# FM33FK5XX register map
File version: 1.0
CPU: Cortex-M33 r1p0, little endian, MPU, FPU, 3 interrupt priority bits
Registers are 32-bit, read-write, reset 0x0 unless marked. A register's access mark holds for its fields unless they carry their own. Offsets are from the block's base; [hi:lo] are bit positions; {n}, {i} and the like mark numbered series.

## CMU — CMU module information
Base 0x40002400
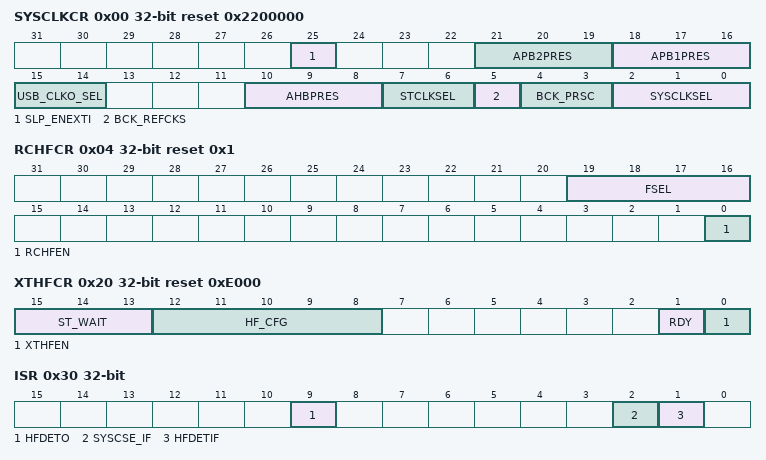
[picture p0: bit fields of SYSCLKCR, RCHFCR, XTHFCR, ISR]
0x00 SYSCLKCR reset 0x2200000 — SystemClockControlRegister
  [25] SLP_ENEXTI — SLP_ENEXTI field description
  [21:19] APB2PRES — APB2PRES field description
  [18:16] APB1PRES — APB1PRES field description
  [15:14] USB_CLKO_SEL — USB_CLKO_SEL field description
  [10:8] AHBPRES — AHBPRES field description
  [7:6] STCLKSEL — STCLKSEL field description
  [5] BCK_REFCKS — BCK_REFCKS field description
  [4:3] BCK_PRSC — BCK_PRSC field description
  [2:0] SYSCLKSEL — SYSCLKSEL field description
0x04 RCHFCR reset 0x1 — RCHFControlRegister
  [19:16] FSEL — FSEL field description
  [0] RCHFEN — RCHFEN field description
0x08 RCHFTR reset 0x80 — RCHFTrimRegister
  [7:0] RCHFTRIM — RCHFTRIM field description
0x10 RCLPCR — RCLPControlRegister
  [0] RCLP_ENB — RCLP_ENB field description
0x14 RCLPTR reset 0x80 — RCLPTrimRegister
  [7:0] RCLP_TRIM — RCLP_TRIM field description
0x20 XTHFCR access per field reset 0xE000 — XTHFControlRegister
  [15:13] ST_WAIT rw — ST_WAIT field description
  [12:8] HF_CFG rw — HF_CFG field description
  [1] RDY ro — RDY field description
  [0] XTHFEN rw — XTHFEN field description
0x2C IER — InterruptEnableRegister
  [1] HFDET_IE — HFDET_IE field description
0x30 ISR access per field — InterruptStatusRegister
  [9] HFDETO ro — HFDETO field description
  [2] SYSCSE_IF rw — SYSCSE_IF field description
  [1] HFDETIF rw — HFDETIF field description
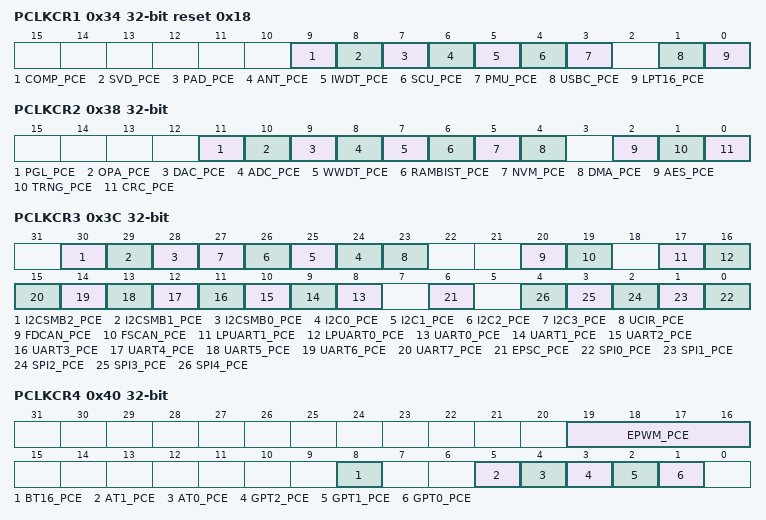
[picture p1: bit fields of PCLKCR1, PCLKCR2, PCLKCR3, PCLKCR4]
0x34 PCLKCR1 reset 0x18 — PeripheralbusClockControlRegister1
  [9] COMP_PCE — COMP_PCE field description
  [8] SVD_PCE — SVD_PCE field description
  [7] PAD_PCE — PAD_PCE field description
  [6] ANT_PCE — ANT_PCE field description
  [5] IWDT_PCE — IWDT_PCE field description
  [4] SCU_PCE — SCU_PCE field description
  [3] PMU_PCE — PMU_PCE field description
  [1] USBC_PCE — USBC_PCE field description
  [0] LPT16_PCE — LPT16_PCE field description
0x38 PCLKCR2 — PeripheralbusClockControlRegister2
  [11] PGL_PCE — PGL_PCE field description
  [10] OPA_PCE — OPA_PCE field description
  [9] DAC_PCE — DAC_PCE field description
  [8] ADC_PCE — ADC_PCE field description
  [7] WWDT_PCE — WWDT_PCE field description
  [6] RAMBIST_PCE — RAMBIST_PCE field description
  [5] NVM_PCE — NVM_PCE field description
  [4] DMA_PCE — DMA_PCE field description
  [2] AES_PCE — AES_PCE field description
  [1] TRNG_PCE — TRNG_PCE field description
  [0] CRC_PCE — CRC_PCE field description
0x3C PCLKCR3 — PeripheralbusClockControlRegister3
  [30] I2CSMB2_PCE — I2CSMB2_PCE field description
  [29] I2CSMB1_PCE — I2CSMB1_PCE field description
  [28] I2CSMB0_PCE — I2CSMB0_PCE field description
  [n+24] I2C{n}_PCE (n=0..3) — I2C{n}_PCE field description
  [23] UCIR_PCE — UCIR_PCE field description
  [20] FDCAN_PCE — FDCAN_PCE field description
  [19] FSCAN_PCE — FSCAN_PCE field description
  [17] LPUART1_PCE — LPUART1_PCE field description
  [16] LPUART0_PCE — LPUART0_PCE field description
  [n+8] UART{n}_PCE (n=0..7) — UART{n}_PCE field description
  [6] EPSC_PCE — EPSC_PCE field description
  [n] SPI{n}_PCE (n=0..4) — SPI{n}_PCE field description
0x40 PCLKCR4 — PeripheralbusClockControlRegister4
  [19:16] EPWM_PCE — EPWM_PCE field description
  [8] BT16_PCE — BT16_PCE field description
  [5] AT1_PCE — AT1_PCE field description
  [4] AT0_PCE — AT0_PCE field description
  [3] GPT2_PCE — GPT2_PCE field description
  [2] GPT1_PCE — GPT1_PCE field description
  [1] GPT0_PCE — GPT0_PCE field description
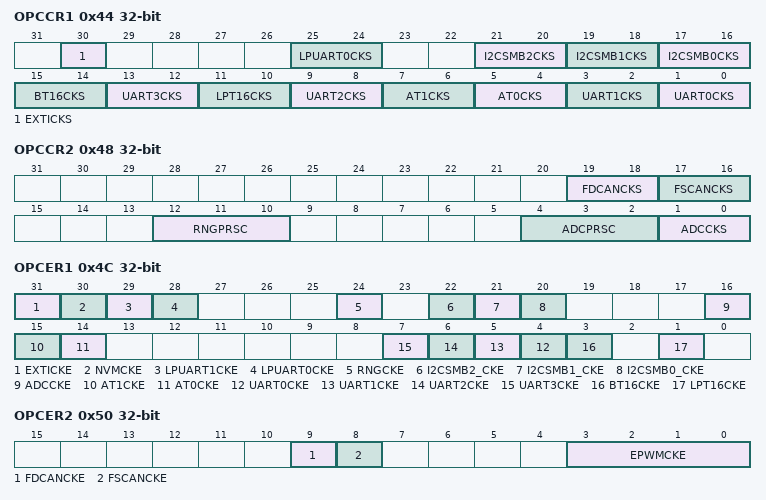
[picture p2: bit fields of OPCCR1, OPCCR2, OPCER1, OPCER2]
0x44 OPCCR1 — PeripheralClockConfigRegister1
  [30] EXTICKS — EXTICKS field description
  [25:24] LPUART0CKS — LPUART0CKS field description
  [21:20] I2CSMB2CKS — I2CSMB2CKS field description
  [19:18] I2CSMB1CKS — I2CSMB1CKS field description
  [17:16] I2CSMB0CKS — I2CSMB0CKS field description
  [15:14] BT16CKS — BT16CKS field description
  [13:12] UART3CKS — UART3CKS field description
  [11:10] LPT16CKS — LPT16CKS field description
  [9:8] UART2CKS — UART2CKS field description
  [7:6] AT1CKS — AT1CKS field description
  [5:4] AT0CKS — AT0CKS field description
  [3:2] UART1CKS — UART1CKS field description
  [1:0] UART0CKS — UART0CKS field description
0x48 OPCCR2 — PeripheralClockConfigRegister2
  [19:18] FDCANCKS — FDCANCKS field description
  [17:16] FSCANCKS — FSCANCKS field description
  [12:10] RNGPRSC — RNGPRSC field description
  [4:2] ADCPRSC — ADCPRSC field description
  [1:0] ADCCKS — ADCCKS field description
0x4C OPCER1 — PeripheralClockEnableRegister
  [31] EXTICKE — EXTICKE field description
  [30] NVMCKE — NVMCKE field description
  [29] LPUART1CKE — LPUART1CKE field description
  [28] LPUART0CKE — LPUART0CKE field description
  [24] RNGCKE — RNGCKE field description
  [22] I2CSMB2_CKE — I2CSMB2_CKE field description
  [21] I2CSMB1_CKE — I2CSMB1_CKE field description
  [20] I2CSMB0_CKE — I2CSMB0_CKE field description
  [16] ADCCKE — ADCCKE field description
  [15] AT1CKE — AT1CKE field description
  [14] AT0CKE — AT0CKE field description
  [n+4] UART{n}CKE (n=0..3) — UART{n}CKE field description
  [3] BT16CKE — BT16CKE field description
  [1] LPT16CKE — LPT16CKE field description
0x50 OPCER2 — PeripheralClockEnableRegister2
  [9] FDCANCKE — FDCANCKE field description
  [8] FSCANCKE — FSCANCKE field description
  [3:0] EPWMCKE — EPWMCKE field description
0x54 AHBMCR — AHBMasterControlRegister
  [0] MPRIL — MPRIL field description
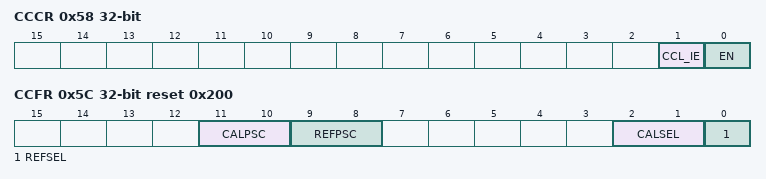
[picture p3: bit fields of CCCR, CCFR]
0x58 CCCR — ClockCalibrationControlRegister
  [1] CCL_IE — CCL_IE field description
  [0] EN — EN field description
0x5C CCFR reset 0x200 — ClockCalibrationConfigRegister
  [11:10] CALPSC — CALPSC field description
  [9:8] REFPSC — REFPSC field description
  [2:1] CALSEL — CALSEL field description
  [0] REFSEL — REFSEL field description
0x60 CCNR ro — ClockCalibrationCounterRegister
  [15:0] CCL_CNT — CCL_CNT field description
0x64 CCISR — ClockCalibrationInterruptStatusRegister
  [0] CCL_IF — CCL_IF field description
